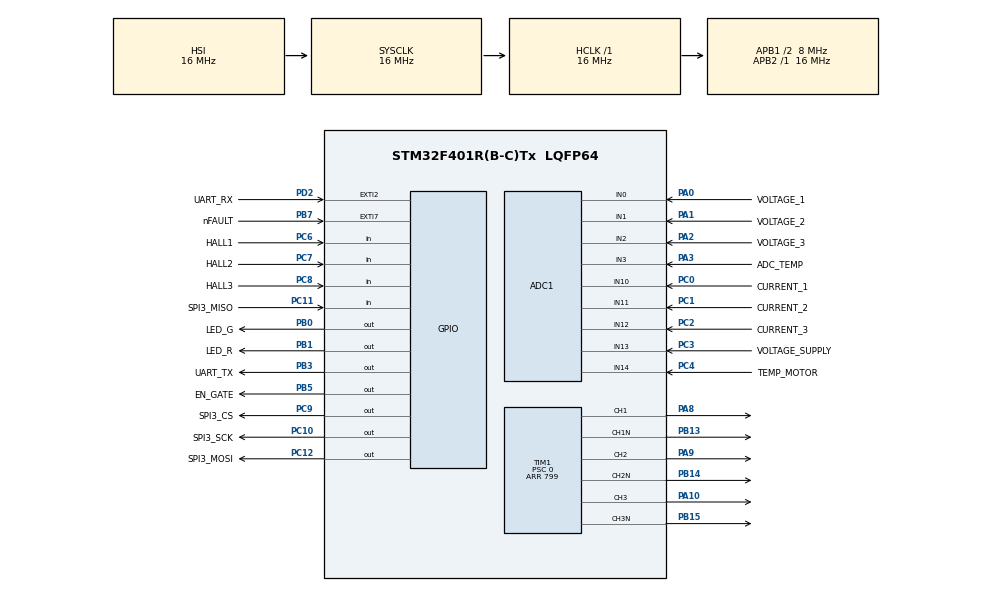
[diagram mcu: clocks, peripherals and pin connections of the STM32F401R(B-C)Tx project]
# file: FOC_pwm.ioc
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ADC1.Channel-1\#ChannelRegularConversion=ADC_CHANNEL_0
ADC1.Channel-2\#ChannelRegularConversion=ADC_CHANNEL_1
ADC1.Channel-3\#ChannelRegularConversion=ADC_CHANNEL_2
ADC1.Channel-4\#ChannelRegularConversion=ADC_CHANNEL_3
ADC1.Channel-5\#ChannelRegularConversion=ADC_CHANNEL_10
ADC1.Channel-6\#ChannelRegularConversion=ADC_CHANNEL_11
ADC1.Channel-7\#ChannelRegularConversion=ADC_CHANNEL_12
ADC1.Channel-8\#ChannelRegularConversion=ADC_CHANNEL_13
ADC1.Channel-9\#ChannelRegularConversion=ADC_CHANNEL_14
ADC1.ClockPrescaler=ADC_CLOCK_SYNC_PCLK_DIV8
ADC1.ContinuousConvMode=ENABLE
ADC1.DMAContinuousRequests=ENABLE
ADC1.DiscontinuousConvMode=DISABLE
ADC1.EOCSelection=ADC_EOC_SEQ_CONV
ADC1.NbrOfConversion=9
ADC1.NbrOfConversionFlag=1
ADC1.Rank-1\#ChannelRegularConversion=1
ADC1.Rank-2\#ChannelRegularConversion=2
ADC1.Rank-3\#ChannelRegularConversion=3
ADC1.Rank-4\#ChannelRegularConversion=4
ADC1.Rank-5\#ChannelRegularConversion=5
ADC1.Rank-6\#ChannelRegularConversion=6
ADC1.Rank-7\#ChannelRegularConversion=7
ADC1.Rank-8\#ChannelRegularConversion=8
ADC1.Rank-9\#ChannelRegularConversion=9
ADC1.SamplingTime-1\#ChannelRegularConversion=ADC_SAMPLETIME_15CYCLES
ADC1.SamplingTime-2\#ChannelRegularConversion=ADC_SAMPLETIME_15CYCLES
ADC1.SamplingTime-3\#ChannelRegularConversion=ADC_SAMPLETIME_15CYCLES
ADC1.SamplingTime-4\#ChannelRegularConversion=ADC_SAMPLETIME_15CYCLES
ADC1.SamplingTime-5\#ChannelRegularConversion=ADC_SAMPLETIME_15CYCLES
ADC1.SamplingTime-6\#ChannelRegularConversion=ADC_SAMPLETIME_15CYCLES
ADC1.SamplingTime-7\#ChannelRegularConversion=ADC_SAMPLETIME_15CYCLES
ADC1.SamplingTime-8\#ChannelRegularConversion=ADC_SAMPLETIME_15CYCLES
ADC1.SamplingTime-9\#ChannelRegularConversion=ADC_SAMPLETIME_15CYCLES
ADC1.master=1
Dma.ADC1.0.Direction=DMA_PERIPH_TO_MEMORY
Dma.ADC1.0.FIFOMode=DMA_FIFOMODE_DISABLE
Dma.ADC1.0.Instance=DMA2_Stream0
Dma.ADC1.0.MemDataAlignment=DMA_MDATAALIGN_WORD
Dma.ADC1.0.MemInc=DMA_MINC_ENABLE
Dma.ADC1.0.Mode=DMA_CIRCULAR
Dma.ADC1.0.PeriphDataAlignment=DMA_PDATAALIGN_WORD
Dma.ADC1.0.PeriphInc=DMA_PINC_DISABLE
Dma.ADC1.0.Priority=DMA_PRIORITY_LOW
Dma.Request0=ADC1
Mcu.Family=STM32F4
Mcu.Name=STM32F401R(B-C)Tx
Mcu.Package=LQFP64
NVIC.DMA2_Stream0_IRQn=true\:0\:0\:false\:false\:true\:false\:true\:true
NVIC.EXTI2_IRQn=true\:0\:0\:false\:false\:true\:true\:true\:true
NVIC.EXTI9_5_IRQn=true\:0\:0\:false\:false\:true\:true\:true\:true
NVIC.PriorityGroup=NVIC_PRIORITYGROUP_4
NVIC.TIM3_IRQn=true\:0\:0\:false\:false\:true\:true\:true\:true
NVIC.TIM4_IRQn=true\:0\:0\:false\:false\:true\:true\:true\:true
NVIC.TIM5_IRQn=true\:0\:0\:false\:false\:true\:true\:true\:true
PA0-WKUP.GPIO_Label=VOLTAGE_1
PA0-WKUP.Signal=ADCx_IN0
PA1.GPIO_Label=VOLTAGE_2
PA1.Signal=ADCx_IN1
PA10.GPIO_PuPd=GPIO_NOPULL
PA10.GPIO_Speed=GPIO_SPEED_FREQ_LOW
PA10.Signal=S_TIM1_CH3
PA13.Mode=Serial_Wire
PA13.Signal=SYS_JTMS-SWDIO
PA14.Mode=Serial_Wire
PA14.Signal=SYS_JTCK-SWCLK
PA2.GPIO_Label=VOLTAGE_3
PA2.Signal=ADCx_IN2
PA3.GPIO_Label=ADC_TEMP
PA3.Signal=ADCx_IN3
PA8.GPIO_PuPd=GPIO_NOPULL
PA8.GPIO_Speed=GPIO_SPEED_FREQ_LOW
PA8.Signal=S_TIM1_CH1
PA9.GPIO_PuPd=GPIO_NOPULL
PA9.GPIO_Speed=GPIO_SPEED_FREQ_LOW
PA9.Signal=S_TIM1_CH2
PB0.GPIO_Label=LED_G
PB0.GPIO_PuPd=GPIO_NOPULL
PB0.Signal=GPIO_Output
PB1.GPIO_Label=LED_R
PB1.Signal=GPIO_Output
PB13.GPIO_PuPd=GPIO_NOPULL
PB13.GPIO_Speed=GPIO_SPEED_FREQ_LOW
PB13.Mode=PWM Generation1 CH1 CH1N
PB13.Signal=TIM1_CH1N
PB14.GPIO_PuPd=GPIO_NOPULL
PB14.GPIO_Speed=GPIO_SPEED_FREQ_LOW
PB14.Mode=PWM Generation2 CH2 CH2N
PB14.Signal=TIM1_CH2N
PB15.GPIO_PuPd=GPIO_NOPULL
PB15.GPIO_Speed=GPIO_SPEED_FREQ_LOW
PB15.Mode=PWM Generation3 CH3 CH3N
PB15.Signal=TIM1_CH3N
PB3.GPIO_Label=UART_TX
PB3.GPIO_Speed=GPIO_SPEED_FREQ_VERY_HIGH
PB3.PinState=GPIO_PIN_SET
PB3.Signal=GPIO_Output
PB5.GPIO_Label=EN_GATE
PB5.PinState=GPIO_PIN_RESET
PB5.Signal=GPIO_Output
PB7.GPIO_Label=nFAULT
PB7.GPIO_ModeDefaultEXTI=GPIO_MODE_IT_RISING_FALLING
PB7.GPIO_PuPd=GPIO_PULLUP
PB7.Signal=GPXTI7
PC0.GPIO_Label=CURRENT_1
PC0.Signal=ADCx_IN10
PC1.GPIO_Label=CURRENT_2
PC1.Signal=ADCx_IN11
PC10.GPIO_Label=SPI3_SCK
PC10.GPIO_Speed=GPIO_SPEED_FREQ_VERY_HIGH
PC10.Signal=GPIO_Output
PC11.GPIO_Label=SPI3_MISO
PC11.Signal=GPIO_Input
PC12.GPIO_Label=SPI3_MOSI
PC12.GPIO_Speed=GPIO_SPEED_FREQ_VERY_HIGH
PC12.Signal=GPIO_Output
PC2.GPIO_Label=CURRENT_3
PC2.Signal=ADCx_IN12
PC3.GPIO_Label=VOLTAGE_SUPPLY
PC3.Signal=ADCx_IN13
PC4.GPIO_Label=TEMP_MOTOR
PC4.Signal=ADCx_IN14
PC6.GPIO_Label=HALL1
PC6.GPIO_PuPd=GPIO_PULLUP
PC6.Signal=GPIO_Input
PC7.GPIO_Label=HALL2
PC7.GPIO_PuPd=GPIO_PULLUP
PC7.Signal=GPIO_Input
PC8.GPIO_Label=HALL3
PC8.GPIO_PuPd=GPIO_PULLUP
PC8.Signal=GPIO_Input
PC9.GPIO_Label=SPI3_CS
PC9.GPIO_Speed=GPIO_SPEED_FREQ_VERY_HIGH
PC9.Signal=GPIO_Output
PD2.GPIO_Label=UART_RX
PD2.GPIO_ModeDefaultEXTI=GPIO_MODE_IT_FALLING
PD2.GPIO_PuPd=GPIO_PULLUP
PD2.Signal=GPXTI2
PH0\ -\ OSC_IN.Mode=HSE-External-Oscillator
PH0\ -\ OSC_IN.Signal=RCC_OSC_IN
PH1\ -\ OSC_OUT.Mode=HSE-External-Oscillator
PH1\ -\ OSC_OUT.Signal=RCC_OSC_OUT
ProjectManager.HeapSize=0x200
ProjectManager.StackSize=0x400
ProjectManager.TargetToolchain=STM32CubeIDE
RCC.48MHZClocksFreq_Value=42000000
RCC.AHBFreq_Value=16000000
RCC.APB1CLKDivider=RCC_HCLK_DIV2
RCC.APB1Freq_Value=8000000
RCC.APB1TimFreq_Value=16000000
RCC.APB2Freq_Value=16000000
RCC.APB2TimFreq_Value=16000000
RCC.CortexFreq_Value=16000000
RCC.HCLKFreq_Value=16000000
RCC.HSE_VALUE=8000000
RCC.HSI_VALUE=16000000
RCC.LSE_VALUE=32768
RCC.PLLM=8
RCC.PLLN=84
RCC.SYSCLKFreq_VALUE=16000000
RCC.VCOOutputFreq_Value=168000000
SH.ADCx_IN0.0=ADC1_IN0,IN0
SH.ADCx_IN1.0=ADC1_IN1,IN1
SH.ADCx_IN10.0=ADC1_IN10,IN10
SH.ADCx_IN11.0=ADC1_IN11,IN11
SH.ADCx_IN12.0=ADC1_IN12,IN12
SH.ADCx_IN13.0=ADC1_IN13,IN13
SH.ADCx_IN14.0=ADC1_IN14,IN14
SH.ADCx_IN2.0=ADC1_IN2,IN2
SH.ADCx_IN3.0=ADC1_IN3,IN3
SH.S_TIM1_CH1.0=TIM1_CH1,PWM Generation1 CH1 CH1N
SH.S_TIM1_CH2.0=TIM1_CH2,PWM Generation2 CH2 CH2N
SH.S_TIM1_CH3.0=TIM1_CH3,PWM Generation3 CH3 CH3N
TIM1.AutomaticOutput=TIM_AUTOMATICOUTPUT_DISABLE
TIM1.BreakPolarity=TIM_BREAKPOLARITY_LOW
TIM1.BreakState=TIM_BREAK_DISABLE
TIM1.Channel-PWM\ Generation1\ CH1\ CH1N=TIM_CHANNEL_1
TIM1.Channel-PWM\ Generation2\ CH2\ CH2N=TIM_CHANNEL_2
TIM1.Channel-PWM\ Generation3\ CH3\ CH3N=TIM_CHANNEL_3
TIM1.DeadTime=0
TIM1.OCFastMode_PWM-PWM\ Generation1\ CH1\ CH1N=TIM_OCFAST_DISABLE
TIM1.OCFastMode_PWM-PWM\ Generation2\ CH2\ CH2N=TIM_OCFAST_DISABLE
TIM1.OCFastMode_PWM-PWM\ Generation3\ CH3\ CH3N=TIM_OCFAST_DISABLE
TIM1.OCIdleState_1=TIM_OCIDLESTATE_RESET
TIM1.OCIdleState_2=TIM_OCIDLESTATE_RESET
TIM1.OCIdleState_3=TIM_OCIDLESTATE_RESET
TIM1.OCMode_PWM-PWM\ Generation1\ CH1\ CH1N=TIM_OCMODE_PWM2
TIM1.OCMode_PWM-PWM\ Generation2\ CH2\ CH2N=TIM_OCMODE_PWM2
TIM1.OCMode_PWM-PWM\ Generation3\ CH3\ CH3N=TIM_OCMODE_PWM2
TIM1.OCNIdleState_1=TIM_OCNIDLESTATE_RESET
TIM1.OCNIdleState_2=TIM_OCNIDLESTATE_RESET
TIM1.OCNIdleState_3=TIM_OCNIDLESTATE_RESET
TIM1.OCNPolarity_1=TIM_OCNPOLARITY_LOW
TIM1.OCNPolarity_2=TIM_OCNPOLARITY_LOW
TIM1.OCNPolarity_3=TIM_OCNPOLARITY_LOW
TIM1.OCPolarity_1=TIM_OCPOLARITY_LOW
TIM1.OCPolarity_2=TIM_OCPOLARITY_LOW
TIM1.OCPolarity_3=TIM_OCPOLARITY_LOW
TIM1.OffStateIDLEMode=TIM_OSSI_DISABLE
TIM1.OffStateRunMode=TIM_OSSR_DISABLE
TIM1.Period=799
TIM1.Prescaler=0
TIM3.Period=999
TIM3.Prescaler=15999
TIM4.Period=1665
TIM4.Prescaler=0
TIM5.Period=1665
TIM5.Prescaler=0
VP_TIM3_VS_ClockSourceINT.Mode=Internal
VP_TIM4_VS_ClockSourceINT.Mode=Internal
VP_TIM5_VS_ClockSourceINT.Mode=Internal
board=custom

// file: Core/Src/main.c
/* USER CODE BEGIN Header */
/**
  ******************************************************************************
  * @file           : main.c
  * @brief          : Main program body
  ******************************************************************************
  * @attention
  *
  * Copyright (c) 2024 STMicroelectronics.
  * All rights reserved.
  *
  * This software is licensed under terms that can be found in the LICENSE file
  * in the root directory of this software component.
  * If no LICENSE file comes with this software, it is provided AS-IS.
  *
  ******************************************************************************
  */
/* USER CODE END Header */
#include "main.h"

ADC_HandleTypeDef hadc1;
DMA_HandleTypeDef hdma_adc1;

TIM_HandleTypeDef htim1;
TIM_HandleTypeDef htim3;
TIM_HandleTypeDef htim4;
TIM_HandleTypeDef htim5;

/* USER CODE BEGIN PV */
/**
 *	8 = TEMP_MOTOR
 *	7 = V_SUPPLY
 *	6 = CURRENT_3
 *	5 = CURRENT_2
 *	4 = CURRENT-1
 *	3 = ADC_TEMP
 *	2 = VOLTAGE_3
 *	1 = VOLTAGE_2
 *	0 = VOLTAGE_1
 */
uint32_t adc_buffer[ADC_CHANNELS];

/* USER CODE END PV */

void SystemClock_Config(void);
static void MX_GPIO_Init(void);
static void MX_DMA_Init(void);
static void MX_TIM3_Init(void);
static void MX_TIM1_Init(void);
static void MX_ADC1_Init(void);
static void MX_TIM4_Init(void);
static void MX_TIM5_Init(void);

int main(void)
{

  /* MCU Configuration--------------------------------------------------------*/

  /* Reset of all peripherals, Initializes the Flash interface and the Systick. */
  HAL_Init();

  /* Configure the system clock */
  SystemClock_Config();

  /* Initialize all configured peripherals */
  MX_GPIO_Init();
  MX_DMA_Init();
  MX_TIM3_Init();
  MX_TIM1_Init();
  MX_ADC1_Init();
  MX_TIM4_Init();
  MX_TIM5_Init();
  /* USER CODE BEGIN 2 */

  HAL_ADC_Start_DMA(&hadc1, adc_buffer, ADC_CHANNELS);
  drv8301_init();
  uart_init();
  motor_init();

  /* USER CODE END 2 */

  /* Infinite loop */
  /* USER CODE BEGIN WHILE */
  while (1)
  {
	  comm();
	  motor_rotate(0);

    /* USER CODE END WHILE */

  }
}

void SystemClock_Config(void)
{
  RCC_OscInitTypeDef RCC_OscInitStruct = {0};
  RCC_ClkInitTypeDef RCC_ClkInitStruct = {0};

  /** Configure the main internal regulator output voltage
  */
  __HAL_RCC_PWR_CLK_ENABLE();
  __HAL_PWR_VOLTAGESCALING_CONFIG(PWR_REGULATOR_VOLTAGE_SCALE2);

  /** Initializes the RCC Oscillators according to the specified parameters
  * in the RCC_OscInitTypeDef structure.
  */
  RCC_OscInitStruct.OscillatorType = RCC_OSCILLATORTYPE_HSI;
  RCC_OscInitStruct.HSIState = RCC_HSI_ON;
  RCC_OscInitStruct.HSICalibrationValue = RCC_HSICALIBRATION_DEFAULT;
  RCC_OscInitStruct.PLL.PLLState = RCC_PLL_NONE;
  if (HAL_RCC_OscConfig(&RCC_OscInitStruct) != HAL_OK)
  {
    Error_Handler();
  }

  /** Initializes the CPU, AHB and APB buses clocks
  */
  RCC_ClkInitStruct.ClockType = RCC_CLOCKTYPE_HCLK|RCC_CLOCKTYPE_SYSCLK
                              |RCC_CLOCKTYPE_PCLK1|RCC_CLOCKTYPE_PCLK2;
  RCC_ClkInitStruct.SYSCLKSource = RCC_SYSCLKSOURCE_HSI;
  RCC_ClkInitStruct.AHBCLKDivider = RCC_SYSCLK_DIV1;
  RCC_ClkInitStruct.APB1CLKDivider = RCC_HCLK_DIV2;
  RCC_ClkInitStruct.APB2CLKDivider = RCC_HCLK_DIV1;

  if (HAL_RCC_ClockConfig(&RCC_ClkInitStruct, FLASH_LATENCY_0) != HAL_OK)
  {
    Error_Handler();
  }
}

static void MX_ADC1_Init(void)
{

  ADC_ChannelConfTypeDef sConfig = {0};

  /** Configure the global features of the ADC (Clock, Resolution, Data Alignment and number of conversion)
  */
  hadc1.Instance = ADC1;
  hadc1.Init.ClockPrescaler = ADC_CLOCK_SYNC_PCLK_DIV8;
  hadc1.Init.Resolution = ADC_RESOLUTION_12B;
  hadc1.Init.ScanConvMode = ENABLE;
  hadc1.Init.ContinuousConvMode = ENABLE;
  hadc1.Init.DiscontinuousConvMode = DISABLE;
  hadc1.Init.ExternalTrigConvEdge = ADC_EXTERNALTRIGCONVEDGE_NONE;
  hadc1.Init.ExternalTrigConv = ADC_SOFTWARE_START;
  hadc1.Init.DataAlign = ADC_DATAALIGN_RIGHT;
  hadc1.Init.NbrOfConversion = 9;
  hadc1.Init.DMAContinuousRequests = ENABLE;
  hadc1.Init.EOCSelection = ADC_EOC_SEQ_CONV;
  if (HAL_ADC_Init(&hadc1) != HAL_OK)
  {
    Error_Handler();
  }

  /** Configure for the selected ADC regular channel its corresponding rank in the sequencer and its sample time.
  */
  sConfig.Channel = ADC_CHANNEL_0;
  sConfig.Rank = 1;
  sConfig.SamplingTime = ADC_SAMPLETIME_15CYCLES;
  if (HAL_ADC_ConfigChannel(&hadc1, &sConfig) != HAL_OK)
  {
    Error_Handler();
  }

  /** Configure for the selected ADC regular channel its corresponding rank in the sequencer and its sample time.
  */
  sConfig.Channel = ADC_CHANNEL_1;
  sConfig.Rank = 2;
  if (HAL_ADC_ConfigChannel(&hadc1, &sConfig) != HAL_OK)
  {
    Error_Handler();
  }

  /** Configure for the selected ADC regular channel its corresponding rank in the sequencer and its sample time.
  */
  sConfig.Channel = ADC_CHANNEL_2;
  sConfig.Rank = 3;
  if (HAL_ADC_ConfigChannel(&hadc1, &sConfig) != HAL_OK)
  {
    Error_Handler();
  }

  /** Configure for the selected ADC regular channel its corresponding rank in the sequencer and its sample time.
  */
  sConfig.Channel = ADC_CHANNEL_3;
  sConfig.Rank = 4;
  if (HAL_ADC_ConfigChannel(&hadc1, &sConfig) != HAL_OK)
  {
    Error_Handler();
  }

  /** Configure for the selected ADC regular channel its corresponding rank in the sequencer and its sample time.
  */
  sConfig.Channel = ADC_CHANNEL_10;
  sConfig.Rank = 5;
  if (HAL_ADC_ConfigChannel(&hadc1, &sConfig) != HAL_OK)
  {
    Error_Handler();
  }

  /** Configure for the selected ADC regular channel its corresponding rank in the sequencer and its sample time.
  */
  sConfig.Channel = ADC_CHANNEL_11;
  sConfig.Rank = 6;
  if (HAL_ADC_ConfigChannel(&hadc1, &sConfig) != HAL_OK)
  {
    Error_Handler();
  }

  /** Configure for the selected ADC regular channel its corresponding rank in the sequencer and its sample time.
  */
  sConfig.Channel = ADC_CHANNEL_12;
  sConfig.Rank = 7;
  if (HAL_ADC_ConfigChannel(&hadc1, &sConfig) != HAL_OK)
  {
    Error_Handler();
  }

  /** Configure for the selected ADC regular channel its corresponding rank in the sequencer and its sample time.
  */
  sConfig.Channel = ADC_CHANNEL_13;
  sConfig.Rank = 8;
  if (HAL_ADC_ConfigChannel(&hadc1, &sConfig) != HAL_OK)
  {
    Error_Handler();
  }

  /** Configure for the selected ADC regular channel its corresponding rank in the sequencer and its sample time.
  */
  sConfig.Channel = ADC_CHANNEL_14;
  sConfig.Rank = 9;
  if (HAL_ADC_ConfigChannel(&hadc1, &sConfig) != HAL_OK)
  {
    Error_Handler();
  }

}

static void MX_TIM1_Init(void)
{

  TIM_MasterConfigTypeDef sMasterConfig = {0};
  TIM_OC_InitTypeDef sConfigOC = {0};
  TIM_BreakDeadTimeConfigTypeDef sBreakDeadTimeConfig = {0};

  htim1.Instance = TIM1;
  htim1.Init.Prescaler = 0;
  htim1.Init.CounterMode = TIM_COUNTERMODE_UP;
  htim1.Init.Period = 799;
  htim1.Init.ClockDivision = TIM_CLOCKDIVISION_DIV1;
  htim1.Init.RepetitionCounter = 0;
  htim1.Init.AutoReloadPreload = TIM_AUTORELOAD_PRELOAD_DISABLE;
  if (HAL_TIM_PWM_Init(&htim1) != HAL_OK)
  {
    Error_Handler();
  }
  sMasterConfig.MasterOutputTrigger = TIM_TRGO_RESET;
  sMasterConfig.MasterSlaveMode = TIM_MASTERSLAVEMODE_DISABLE;
  if (HAL_TIMEx_MasterConfigSynchronization(&htim1, &sMasterConfig) != HAL_OK)
  {
    Error_Handler();
  }
  sConfigOC.OCMode = TIM_OCMODE_PWM2;
  sConfigOC.Pulse = 0;
  sConfigOC.OCPolarity = TIM_OCPOLARITY_LOW;
  sConfigOC.OCNPolarity = TIM_OCNPOLARITY_LOW;
  sConfigOC.OCFastMode = TIM_OCFAST_DISABLE;
  sConfigOC.OCIdleState = TIM_OCIDLESTATE_RESET;
  sConfigOC.OCNIdleState = TIM_OCNIDLESTATE_RESET;
  if (HAL_TIM_PWM_ConfigChannel(&htim1, &sConfigOC, TIM_CHANNEL_1) != HAL_OK)
  {
    Error_Handler();
  }
  if (HAL_TIM_PWM_ConfigChannel(&htim1, &sConfigOC, TIM_CHANNEL_2) != HAL_OK)
  {
    Error_Handler();
  }
  if (HAL_TIM_PWM_ConfigChannel(&htim1, &sConfigOC, TIM_CHANNEL_3) != HAL_OK)
  {
    Error_Handler();
  }
  sBreakDeadTimeConfig.OffStateRunMode = TIM_OSSR_DISABLE;
  sBreakDeadTimeConfig.OffStateIDLEMode = TIM_OSSI_DISABLE;
  sBreakDeadTimeConfig.LockLevel = TIM_LOCKLEVEL_OFF;
  sBreakDeadTimeConfig.DeadTime = 0;
  sBreakDeadTimeConfig.BreakState = TIM_BREAK_DISABLE;
  sBreakDeadTimeConfig.BreakPolarity = TIM_BREAKPOLARITY_LOW;
  sBreakDeadTimeConfig.AutomaticOutput = TIM_AUTOMATICOUTPUT_DISABLE;
  if (HAL_TIMEx_ConfigBreakDeadTime(&htim1, &sBreakDeadTimeConfig) != HAL_OK)
  {
    Error_Handler();
  }
  HAL_TIM_MspPostInit(&htim1);

}

static void MX_TIM3_Init(void)
{

  TIM_ClockConfigTypeDef sClockSourceConfig = {0};
  TIM_MasterConfigTypeDef sMasterConfig = {0};

  htim3.Instance = TIM3;
  htim3.Init.Prescaler = 15999;
  htim3.Init.CounterMode = TIM_COUNTERMODE_UP;
  htim3.Init.Period = 999;
  htim3.Init.ClockDivision = TIM_CLOCKDIVISION_DIV1;
  htim3.Init.AutoReloadPreload = TIM_AUTORELOAD_PRELOAD_DISABLE;
  if (HAL_TIM_Base_Init(&htim3) != HAL_OK)
  {
    Error_Handler();
  }
  sClockSourceConfig.ClockSource = TIM_CLOCKSOURCE_INTERNAL;
  if (HAL_TIM_ConfigClockSource(&htim3, &sClockSourceConfig) != HAL_OK)
  {
    Error_Handler();
  }
  sMasterConfig.MasterOutputTrigger = TIM_TRGO_RESET;
  sMasterConfig.MasterSlaveMode = TIM_MASTERSLAVEMODE_DISABLE;
  if (HAL_TIMEx_MasterConfigSynchronization(&htim3, &sMasterConfig) != HAL_OK)
  {
    Error_Handler();
  }

}

static void MX_TIM4_Init(void)
{

  TIM_ClockConfigTypeDef sClockSourceConfig = {0};
  TIM_MasterConfigTypeDef sMasterConfig = {0};

  htim4.Instance = TIM4;
  htim4.Init.Prescaler = 0;
  htim4.Init.CounterMode = TIM_COUNTERMODE_UP;
  htim4.Init.Period = 1665;
  htim4.Init.ClockDivision = TIM_CLOCKDIVISION_DIV1;
  htim4.Init.AutoReloadPreload = TIM_AUTORELOAD_PRELOAD_DISABLE;
  if (HAL_TIM_Base_Init(&htim4) != HAL_OK)
  {
    Error_Handler();
  }
  sClockSourceConfig.ClockSource = TIM_CLOCKSOURCE_INTERNAL;
  if (HAL_TIM_ConfigClockSource(&htim4, &sClockSourceConfig) != HAL_OK)
  {
    Error_Handler();
  }
  sMasterConfig.MasterOutputTrigger = TIM_TRGO_RESET;
  sMasterConfig.MasterSlaveMode = TIM_MASTERSLAVEMODE_DISABLE;
  if (HAL_TIMEx_MasterConfigSynchronization(&htim4, &sMasterConfig) != HAL_OK)
  {
    Error_Handler();
  }

}

static void MX_TIM5_Init(void)
{

  TIM_ClockConfigTypeDef sClockSourceConfig = {0};
  TIM_MasterConfigTypeDef sMasterConfig = {0};

  htim5.Instance = TIM5;
  htim5.Init.Prescaler = 0;
  htim5.Init.CounterMode = TIM_COUNTERMODE_UP;
  htim5.Init.Period = 1665;
  htim5.Init.ClockDivision = TIM_CLOCKDIVISION_DIV1;
  htim5.Init.AutoReloadPreload = TIM_AUTORELOAD_PRELOAD_DISABLE;
  if (HAL_TIM_Base_Init(&htim5) != HAL_OK)
  {
    Error_Handler();
  }
  sClockSourceConfig.ClockSource = TIM_CLOCKSOURCE_INTERNAL;
  if (HAL_TIM_ConfigClockSource(&htim5, &sClockSourceConfig) != HAL_OK)
  {
    Error_Handler();
  }
  sMasterConfig.MasterOutputTrigger = TIM_TRGO_RESET;
  sMasterConfig.MasterSlaveMode = TIM_MASTERSLAVEMODE_DISABLE;
  if (HAL_TIMEx_MasterConfigSynchronization(&htim5, &sMasterConfig) != HAL_OK)
  {
    Error_Handler();
  }

}

static void MX_DMA_Init(void)
{

  /* DMA controller clock enable */
  __HAL_RCC_DMA2_CLK_ENABLE();

  /* DMA interrupt init */
  /* DMA2_Stream0_IRQn interrupt configuration */
  HAL_NVIC_SetPriority(DMA2_Stream0_IRQn, 0, 0);
  HAL_NVIC_EnableIRQ(DMA2_Stream0_IRQn);

}

static void MX_GPIO_Init(void)
{
  GPIO_InitTypeDef GPIO_InitStruct = {0};

  /* GPIO Ports Clock Enable */
  __HAL_RCC_GPIOH_CLK_ENABLE();
  __HAL_RCC_GPIOC_CLK_ENABLE();
  __HAL_RCC_GPIOA_CLK_ENABLE();
  __HAL_RCC_GPIOB_CLK_ENABLE();
  __HAL_RCC_GPIOD_CLK_ENABLE();

  /*Configure GPIO pin Output Level */
  HAL_GPIO_WritePin(GPIOB, LED_G_Pin|LED_R_Pin|EN_GATE_Pin, GPIO_PIN_RESET);

  /*Configure GPIO pin Output Level */
  HAL_GPIO_WritePin(GPIOC, SPI3_CS_Pin|SPI3_SCK_Pin|SPI3_MOSI_Pin, GPIO_PIN_RESET);

  /*Configure GPIO pin Output Level */
  HAL_GPIO_WritePin(UART_TX_GPIO_Port, UART_TX_Pin, GPIO_PIN_SET);

  /*Configure GPIO pins : LED_G_Pin LED_R_Pin EN_GATE_Pin */
  GPIO_InitStruct.Pin = LED_G_Pin|LED_R_Pin|EN_GATE_Pin;
  GPIO_InitStruct.Mode = GPIO_MODE_OUTPUT_PP;
  GPIO_InitStruct.Pull = GPIO_NOPULL;
  GPIO_InitStruct.Speed = GPIO_SPEED_FREQ_LOW;
  HAL_GPIO_Init(GPIOB, &GPIO_InitStruct);

  /*Configure GPIO pins : HALL1_Pin HALL2_Pin HALL3_Pin */
  GPIO_InitStruct.Pin = HALL1_Pin|HALL2_Pin|HALL3_Pin;
  GPIO_InitStruct.Mode = GPIO_MODE_INPUT;
  GPIO_InitStruct.Pull = GPIO_PULLUP;
  HAL_GPIO_Init(GPIOC, &GPIO_InitStruct);

  /*Configure GPIO pins : SPI3_CS_Pin SPI3_SCK_Pin SPI3_MOSI_Pin */
  GPIO_InitStruct.Pin = SPI3_CS_Pin|SPI3_SCK_Pin|SPI3_MOSI_Pin;
  GPIO_InitStruct.Mode = GPIO_MODE_OUTPUT_PP;
  GPIO_InitStruct.Pull = GPIO_NOPULL;
  GPIO_InitStruct.Speed = GPIO_SPEED_FREQ_VERY_HIGH;
  HAL_GPIO_Init(GPIOC, &GPIO_InitStruct);

  /*Configure GPIO pin : SPI3_MISO_Pin */
  GPIO_InitStruct.Pin = SPI3_MISO_Pin;
  GPIO_InitStruct.Mode = GPIO_MODE_INPUT;
  GPIO_InitStruct.Pull = GPIO_NOPULL;
  HAL_GPIO_Init(SPI3_MISO_GPIO_Port, &GPIO_InitStruct);

  /*Configure GPIO pin : UART_RX_Pin */
  GPIO_InitStruct.Pin = UART_RX_Pin;
  GPIO_InitStruct.Mode = GPIO_MODE_IT_FALLING;
  GPIO_InitStruct.Pull = GPIO_PULLUP;
  HAL_GPIO_Init(UART_RX_GPIO_Port, &GPIO_InitStruct);

  /*Configure GPIO pin : UART_TX_Pin */
  GPIO_InitStruct.Pin = UART_TX_Pin;
  GPIO_InitStruct.Mode = GPIO_MODE_OUTPUT_PP;
  GPIO_InitStruct.Pull = GPIO_NOPULL;
  GPIO_InitStruct.Speed = GPIO_SPEED_FREQ_VERY_HIGH;
  HAL_GPIO_Init(UART_TX_GPIO_Port, &GPIO_InitStruct);

  /*Configure GPIO pin : nFAULT_Pin */
  GPIO_InitStruct.Pin = nFAULT_Pin;
  GPIO_InitStruct.Mode = GPIO_MODE_IT_RISING_FALLING;
  GPIO_InitStruct.Pull = GPIO_PULLUP;
  HAL_GPIO_Init(nFAULT_GPIO_Port, &GPIO_InitStruct);

  /* EXTI interrupt init*/
  HAL_NVIC_SetPriority(EXTI2_IRQn, 0, 0);
  HAL_NVIC_EnableIRQ(EXTI2_IRQn);

  HAL_NVIC_SetPriority(EXTI9_5_IRQn, 0, 0);
  HAL_NVIC_EnableIRQ(EXTI9_5_IRQn);

}

void Error_Handler(void)
{
  __disable_irq();
  while (1)
  {
  }
}
